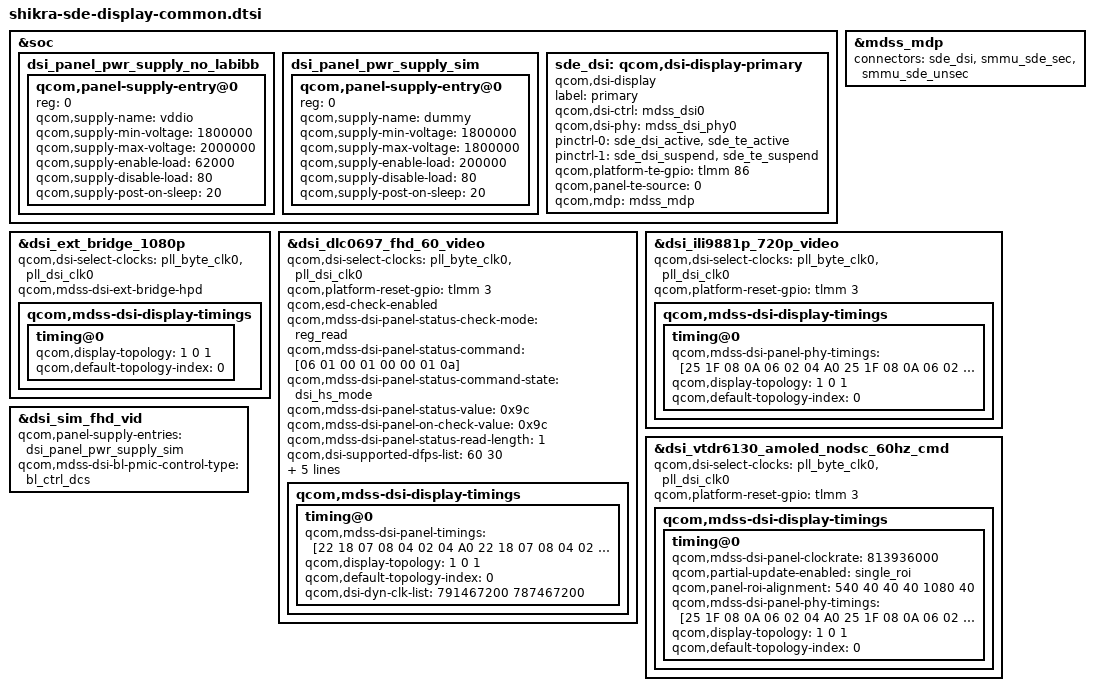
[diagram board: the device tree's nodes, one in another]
// SPDX-License-Identifier: BSD-3-Clause
/*
 * Copyright (c) Qualcomm Technologies, Inc. and/or its subsidiaries.
 */

#include "dsi-panel-ext-bridge-1080p.dtsi"
#include "dsi-panel-dlc0697-fhd-60hz-video.dtsi"
#include "dsi-panel-ili9881p-720p-video.dtsi"
#include "dsi-panel-vtdr6130-nodsc-fhd-plus-60hz-cmd.dtsi"
#include "dsi-panel-sim-fhd-video.dtsi"
#include "shikra-sde-display-pinctrl.dtsi"

&soc {
	dsi_panel_pwr_supply_no_labibb: dsi_panel_pwr_supply_no_labibb {
		#address-cells = <1>;
		#size-cells = <0>;

		qcom,panel-supply-entry@0 {
			reg = <0>;
			qcom,supply-name = "vddio";
			qcom,supply-min-voltage = <1800000>;
			qcom,supply-max-voltage = <2000000>;
			qcom,supply-enable-load = <62000>;
			qcom,supply-disable-load = <80>;
			qcom,supply-post-on-sleep = <20>;
		};
	};

	dsi_panel_pwr_supply_sim: dsi_panel_pwr_supply_sim {
		#address-cells = <1>;
		#size-cells = <0>;

		qcom,panel-supply-entry@0 {
			reg = <0>;
			qcom,supply-name = "dummy";
			qcom,supply-min-voltage = <1800000>;
			qcom,supply-max-voltage = <1800000>;
			qcom,supply-enable-load = <200000>;
			qcom,supply-disable-load = <80>;
			qcom,supply-post-on-sleep = <20>;
		};
	};

	sde_dsi: qcom,dsi-display-primary {
		compatible = "qcom,dsi-display";
		label = "primary";

		qcom,dsi-ctrl = <&mdss_dsi0>;
		qcom,dsi-phy = <&mdss_dsi_phy0>;

		pinctrl-names = "panel_active", "panel_suspend";
		pinctrl-0 = <&sde_dsi_active &sde_te_active>;
		pinctrl-1 = <&sde_dsi_suspend &sde_te_suspend>;

		qcom,platform-te-gpio = <&tlmm 86 0>;
		qcom,panel-te-source = <0>;

		qcom,mdp = <&mdss_mdp>;
	};
};

&mdss_mdp {
	connectors = <&sde_dsi &smmu_sde_sec &smmu_sde_unsec>;
};

// Bridge-ITP/EITP
&dsi_ext_bridge_1080p {
	qcom,dsi-select-clocks = "pll_byte_clk0", "pll_dsi_clk0";
	qcom,mdss-dsi-ext-bridge-hpd;

	qcom,mdss-dsi-display-timings {
		timing@0 {
			qcom,display-topology = <1 0 1>;
			qcom,default-topology-index = <0>;
		};
	};
};

// DLC-ITP/ITPS/EITP
&dsi_dlc0697_fhd_60_video {
	qcom,dsi-select-clocks = "pll_byte_clk0", "pll_dsi_clk0";
	qcom,platform-reset-gpio = <&tlmm 3 0>;

	qcom,esd-check-enabled;
	qcom,mdss-dsi-panel-status-check-mode = "reg_read";
	qcom,mdss-dsi-panel-status-command = [06 01 00 01 00 00 01 0a];
	qcom,mdss-dsi-panel-status-command-state = "dsi_hs_mode";
	qcom,mdss-dsi-panel-status-value = <0x9c>;
	qcom,mdss-dsi-panel-on-check-value = <0x9c>;
	qcom,mdss-dsi-panel-status-read-length = <1>;
	qcom,dsi-supported-dfps-list = <60 30>;
	qcom,mdss-dsi-pan-enable-dynamic-fps;
	qcom,mdss-dsi-pan-fps-update = "dfps_immediate_porch_mode_vfp";
	qcom,dsi-dyn-clk-enable;
	qcom,dsi-dyn-clk-type = "constant-fps-adjust-vfp";
	qcom,mdss-dsi-display-timings {
		timing@0 {
			qcom,mdss-dsi-panel-timings =
				[22 18 07 08 04 02 04 A0
				22 18 07 08 04 02 04 A0
				22 18 07 08 04 02 04 A0
				22 1E 07 08 04 02 04 A0];
			qcom,display-topology = <1 0 1>;
			qcom,default-topology-index = <0>;
			qcom,dsi-dyn-clk-list = <791467200 787467200>;
		};
	};
};

// RPI-COTS
&dsi_ili9881p_720p_video {
	qcom,dsi-select-clocks = "pll_byte_clk0", "pll_dsi_clk0";
	qcom,platform-reset-gpio = <&tlmm 3 0>;

	qcom,mdss-dsi-display-timings {
		timing@0 {
			qcom,mdss-dsi-panel-phy-timings =
			[25 1F 08 0A 06 02 04 A0
			25 1F 08 0A 06 02 04 A0
			25 1F 08 0A 06 02 04 A0
			25 1F 09 0A 06 02 04 A0];
			qcom,display-topology = <1 0 1>;
			qcom,default-topology-index = <0>;
		};
	};
};

// VTDR-ATP
&dsi_vtdr6130_amoled_nodsc_60hz_cmd {
	qcom,dsi-select-clocks = "pll_byte_clk0", "pll_dsi_clk0";
	qcom,platform-reset-gpio = <&tlmm 3 0>;

	qcom,mdss-dsi-display-timings {
		timing@0 {
			qcom,mdss-dsi-panel-clockrate = <813936000>;
			qcom,partial-update-enabled = "single_roi";
			qcom,panel-roi-alignment = <540 40 40 40 1080 40>;
			qcom,mdss-dsi-panel-phy-timings =
			[25 1F 08 0A 06 02 04 A0
			25 1F 08 0A 06 02 04 A0
			25 1F 08 0A 06 02 04 A0
			25 1F 08 0A 06 02 04 A0
			25 1F 09 0A 06 02 04 A0];
			qcom,display-topology = <1 0 1>;
			qcom,default-topology-index = <0>;
		};
	};
};

// FHD-SLT
&dsi_sim_fhd_vid {
	qcom,panel-supply-entries = <&dsi_panel_pwr_supply_sim>;
	qcom,mdss-dsi-bl-pmic-control-type = "bl_ctrl_dcs";
};

